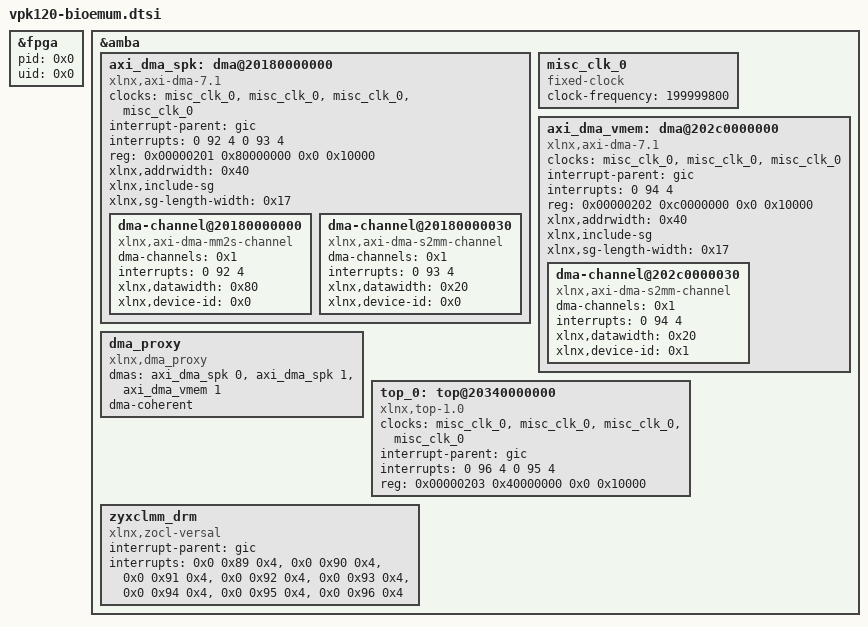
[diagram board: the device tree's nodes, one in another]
/*
 * CAUTION: This file is automatically generated by Xilinx.
 * Version: XSCT 2023.2
 * Today is: Thu Sep 19 12:18:37 2024
 */


/dts-v1/;
/plugin/;
&fpga {
	pid = <0x0>;
	uid = <0x0>;
};
&amba {
	#address-cells = <2>;
	#size-cells = <2>;
	axi_dma_spk: dma@20180000000 {
		#dma-cells = <1>;
		clock-names = "m_axi_mm2s_aclk", "m_axi_s2mm_aclk", "m_axi_sg_aclk", "s_axi_lite_aclk";
		clocks = <&misc_clk_0>, <&misc_clk_0>, <&misc_clk_0>, <&misc_clk_0>;
		compatible = "xlnx,axi-dma-7.1", "xlnx,axi-dma-1.00.a";
		interrupt-names = "mm2s_introut", "s2mm_introut";
		interrupt-parent = <&gic>;
		interrupts = <0 92 4 0 93 4>;
		reg = <0x00000201 0x80000000 0x0 0x10000>;
		xlnx,addrwidth = <0x40>;
		xlnx,include-sg ;
		xlnx,sg-length-width = <0x17>;
		dma-channel@20180000000 {
			compatible = "xlnx,axi-dma-mm2s-channel";
			dma-channels = <0x1>;
			interrupts = <0 92 4>;
			xlnx,datawidth = <0x80>;
			xlnx,device-id = <0x0>;
		};
		dma-channel@20180000030 {
			compatible = "xlnx,axi-dma-s2mm-channel";
			dma-channels = <0x1>;
			interrupts = <0 93 4>;
			xlnx,datawidth = <0x20>;
			xlnx,device-id = <0x0>;
		};
	};
	misc_clk_0: misc_clk_0 {
		#clock-cells = <0>;
		clock-frequency = <199999800>;
		compatible = "fixed-clock";
	};
	axi_dma_vmem: dma@202c0000000 {
		#dma-cells = <1>;
		clock-names = "m_axi_s2mm_aclk", "m_axi_sg_aclk", "s_axi_lite_aclk";
		clocks = <&misc_clk_0>, <&misc_clk_0>, <&misc_clk_0>;
		compatible = "xlnx,axi-dma-7.1", "xlnx,axi-dma-1.00.a";
		interrupt-names = "s2mm_introut";
		interrupt-parent = <&gic>;
		interrupts = <0 94 4>;
		reg = <0x00000202 0xc0000000 0x0 0x10000>;
		xlnx,addrwidth = <0x40>;
		xlnx,include-sg ;
		xlnx,sg-length-width = <0x17>;
		dma-channel@202c0000030 {
			compatible = "xlnx,axi-dma-s2mm-channel";
			dma-channels = <0x1>;
			interrupts = <0 94 4>;
			xlnx,datawidth = <0x20>;
			xlnx,device-id = <0x1>;
		};
	};
	dma_proxy {
		compatible ="xlnx,dma_proxy";
		dmas = <&axi_dma_spk 0 &axi_dma_spk 1 &axi_dma_vmem 1>;
		dma-names = "dma_proxy_tx_ext_stim", "dma_proxy_rx_spk", "dma_proxy_rx_vmem";
		dma-coherent;
	};
	top_0: top@20340000000 {
		/* This is a place holder node for a custom IP, user may need to update the entries */
		clock-names = "M_AXIS_SPK_ACLK", "M_AXIS_VMEM_ACLK", "S00_AXI_LITE_ACLK", "S_AXIS_STIM_ACLK";
		clocks = <&misc_clk_0>, <&misc_clk_0>, <&misc_clk_0>, <&misc_clk_0>;
		compatible = "xlnx,top-1.0";
		interrupt-names = "dma_spk_intr", "dma_vmem_intr";
		interrupt-parent = <&gic>;
		interrupts = <0 96 4 0 95 4>;
		reg = <0x00000203 0x40000000 0x0 0x10000>;
	};
	zyxclmm_drm {
		compatible = "xlnx,zocl-versal";
		interrupt-parent = <&gic>;
		interrupts = <0x0 0x89 0x4>, <0x0 0x90 0x4>, <0x0 0x91 0x4>, <0x0 0x92 0x4>, <0x0 0x93 0x4>, <0x0 0x94 0x4>, <0x0 0x95 0x4>, <0x0 0x96 0x4>;
	};
};
